# SAMA7D65D2GN8 register map
Vendor: Microchip Technology; Series: SAMA7D6; File version: 0
Registers are 32-bit, read-write, reset 0x0 unless marked. A register's access mark holds for its fields unless they carry their own. Offsets are from the block's base; [hi:lo] are bit positions; lines under a group give offsets from that group; <NAME> marks a mode.

## DDRUMCTL (part 4 of 4) — Enhanced Universal DDR-SDRAM Memory Controller
Base 0xE3800000; register names take the prefix UDDRC_
0xF04 SARBASE0 — SAR Base Address Register n
  [2:0] BASE_ADDR — Base address for address region n specified as awaddr[UMCTL2_A_ADDRW-1:x] and araddr[UMCTL2_A_ADDRW-1:x] where 'x' is determined by the minimum block size parameter UMCTL2_SARMINSIZE: (x=log2(block size)). Programming Mode: Static
0xF08 SARSIZE0 — SAR Size Register n
  [7:0] NBLOCKS — Number of blocks for address region n. This register determines the total size of the region in multiples of minimum block size as specified by the hardware parameter UMCTL2_SARMINSIZE. The register value is encoded as number of blocks = nblocks + 1. For example, if register is programmed to 0, region will have 1 block. Programming Mode: Static
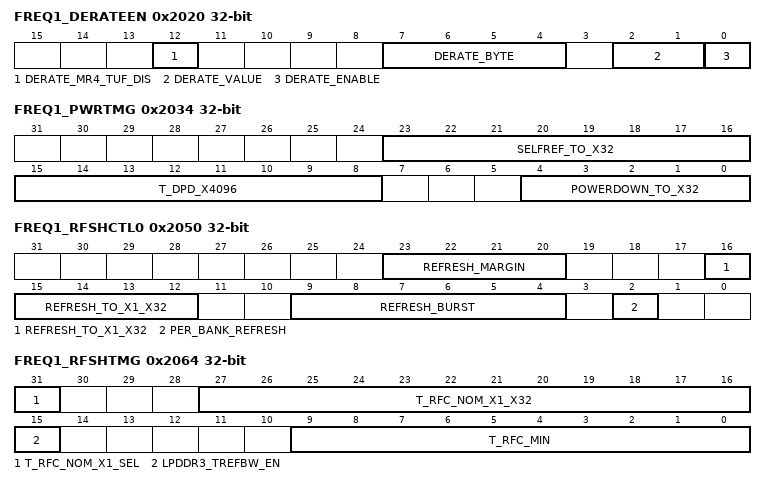
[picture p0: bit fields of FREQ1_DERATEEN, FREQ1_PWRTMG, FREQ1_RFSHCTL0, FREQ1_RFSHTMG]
0x2020 FREQ1_DERATEEN — [FREQ1] Temperature Derate Enable Register
  [12] DERATE_MR4_TUF_DIS — Disable use of MR4 TUF flag (MR4[7]) bit
  [7:4] DERATE_BYTE
  [2:1] DERATE_VALUE
  [0] DERATE_ENABLE — Enables derating
0x2024 FREQ1_DERATEINT reset 0x800000 — [FREQ1] Temperature Derate Interval Register
  [31:0] MR4_READ_INTERVAL — Interval between two MR4 reads
0x2034 FREQ1_PWRTMG — [FREQ1] Low Power Timing Register
  [23:16] SELFREF_TO_X32 — After this many clocks of the DDRC command channel being idle the UDDRC automatically puts the SDRAM into Self-refresh. The DDRC command channel is considered idle when there are no HIF commands outstanding. This must be enabled in the PWRCTL.selfref_en. For performance only. Unit: Multiples of 32 DFI clock cycles. Programming mode: Quasi-dynamic Group 4
  [15:8] T_DPD_X4096 — For LPDDR2/LPDDR3, value from the JEDEC specification is 500 s. Present only in designs configured to support LPDDR2 or LPDDR3. For performance only. Unit: Multiples of 4096 DFI clock cycles. Programming mode: Quasi-dynamic Group 4
  [4:0] POWERDOWN_TO_X32 — After this many clocks of the DDRC command channel being idle the UDDRC automatically puts the SDRAM into Power-down. The DDRC command channel is considered idle when there are no HIF commands outstanding. This must be enabled in the PWRCTL.powerdown_en. For performance only. Unit: Multiples of 32 DFI clock cycles. Programming mode: Quasi-dynamic Group 4
0x2050 FREQ1_RFSHCTL0 — [FREQ1] Refresh Control Register 0
  [23:20] REFRESH_MARGIN — Threshold value in number of DFI clock cycles before the critical refresh or page timer expires. A critical refresh is to be issued before this threshold is reached. It is recommended that this not be changed from the default value, currently shown as 0x2. It must always be less than internally used t_rfc_nom/32. Note that internally used t_rfc_nom is equal to RFSHTMG.t_rfc_nom_x1_x32 * 32 if RFSHTMG.t_rfc_nom_x1_sel=0. If RFSHTMG.t_rfc_nom_x1_sel=1 (for LPDDR2/LPDDR3/LPDDR4 per-bank refresh only), internally used t_rfc_nom is equal to RFSHTMG.t_rfc_nom_x1_x32. Note that, in LPDDR2/LPDDR3/LPDDR4, internally used t_rfc_nom may be divided by four if derating is enabled (DERATEEN.derate_enable=1). Unit: Multiples of 32 DFI clock cycles. Programming Mode: Dynamic - Refresh Related
  [16:12] REFRESH_TO_X1_X32 — If the refresh timer (tRFCnom, also known as tREFI) has expired at least once, then a speculative refresh may be performed. A speculative refresh is a refresh performed at a time when refresh would be useful. When the SDRAM bus is idle for a period of time determined by this RFSHCTL0.refresh_to_x1_x32 and the refresh timer has expired at least once since the last refresh, then a speculative refresh is performed. Speculative refreshes continues successively until there are no refreshes pending or until new reads or writes are issued to the uMCTL2. FOR PERFORMANCE ONLY. Unit: DFI clock cycles or multiples of 32 DFI clock cycles, depending on RFSHTMG.t_rfc_nom_x1_sel. Please refer to 'Note 1' from 'Notes on Timing Registers' at the start of 'Register Descriptions' chapter for details on how to program this register field. Programming Mode: Dynamic - Refresh Related
  [9:4] REFRESH_BURST — The programmed value + 1 is the number of refresh timeouts that is allowed to accumulate before traffic is blocked and the refreshes are forced to execute. Closing pages to perform a refresh is a one-time penalty that must be paid for each group of refreshes. Therefore, performing refreshes in a burst reduces the per-refresh penalty of these page closings. Higher numbers for RFSHCTL.refresh_burst slightly increases utilization; lower numbers decreases the worst-case latency associated with refreshes. - 0 - single refresh - 1 - burst-of-2 refresh - 7 - burst-of-8 refresh For information on burst refresh feature refer to section 3.9 of DDR2 JEDEC specification - JESD79-2F.pdf. For DDR2/3, the refresh is always per-rank and not per-bank. The rank refresh can be accumulated over 8*tREFI cycles using the burst refresh feature. In DDR4 mode, according to Fine Granularity feature, 8 refreshes can be postponed in 1X mode, 16 refreshes in 2X mode and 32 refreshes in 4X mode. If using PHY-initiated updates, care must be taken in the setting of RFSHCTL0.refresh_burst, to ensure that tRFCmax is not violated due to a PHY-initiated update occurring shortly before a refresh burst was due. In this situation, the refresh burst will be delayed until the PHY-initiated update is complete. In per-bank refresh mode of LPDDR2/LPDDR3/LPDDR4 (RFSHCTL0.per_bank_refresh = 1), 64 refreshes can be postponed. Programming Mode: Dynamic - Refresh Related
  [2] PER_BANK_REFRESH — - 1 - Per bank refresh - 0 - All bank refresh Per bank refresh allows traffic to flow to other banks. Per bank refresh is not supported by all LPDDR2 devices but should be supported by all LPDDR3/LPDDR4 devices. Present only in designs configured to support LPDDR2/LPDDR3/LPDDR4 Programming Mode: Static
0x2064 FREQ1_RFSHTMG — [FREQ1] Refresh Timing Register
  [31] T_RFC_NOM_X1_SEL — Specifies whether the RFSHTMG.t_rfc_nom_x1_x32 and RFSHCTL0.refresh_to_x1_x32 register values are x1 or x32. - 0 - x32 register values are used - 1 - x1 register values are used. This applies only when per-bank refresh is enabled (RFSHCTL0.per_bank_refresh=1); if per-bank refresh is not enabled, the x32 register values are used and this register field is ignored Programming Mode: Dynamic - Refresh Related
  [27:16] T_RFC_NOM_X1_X32 — Average time interval between refreshes per rank (Specification: 7.8us for DDR2, DDR3 and DDR4. See JEDEC specification for mDDR, LPDDR2, LPDDR3 and LPDDR4). When the controller is operating in 1:1 mode, set this register to RoundDown(tREFI/tCK) When the controller is operating in 1:2 mode, set this register to RoundDown(RoundDown(tREFI/tCK)/2) In both the above cases, if RFSHTMG.t_rfc_nom_x1_sel = 0, divide the above result by 32 and round down. For LPDDR2/LPDDR3/LPDDR4: - if using all-bank refreshes (RFSHCTL0.per_bank_refresh = 0), use tREFIab in the above calculations - if using per-bank refreshes (RFSHCTL0.per_bank_refresh = 1), use tREFIpb in the above calculations For DDR4 mode, tREFI value is different depending on the refresh mode. The user should program the appropriate value from the spec based on the value programmed in the refresh mode register. Note that: - RFSHTMG.t_rfc_nom_x1_x32 must be greater than 0x1. - if RFSHTMG.t_rfc_nom_x1_sel == 1, RFSHTMG.t_rfc_nom_x1_x32 must be greater than RFSHTMG.t_rfc_min - if RFSHTMG.t_rfc_nom_x1_sel == 0, RFSHTMG.t_rfc_nom_x1_x32 * 32 must be greater than RFSHTMG.t_rfc_min - In non-DDR4 or DDR4 Fixed 1x mode: RFSHTMG.t_rfc_nom_x1_x32 must be less than or equal to 0xFFE. - In DDR4 Fixed 2x mode: RFSHTMG.t_rfc_nom_x1_x32 must be less than or equal to 0x7FF. - In DDR4 Fixed 4x mode: RFSHTMG.t_rfc_nom_x1_x32 must be less than or equal to 0x3FF. Unit: DFI clock cycles or multiples of 32 DFI clock cycles, depending on RFSHTMG.t_rfc_nom_x1_sel. Please refer to 'Note 1' from 'Notes on Timing Registers' at the start of 'Register Descriptions' chapter for details on how to program this register field. Programming Mode: Dynamic - Refresh Related
  [15] LPDDR3_TREFBW_EN — Used only when LPDDR3 memory type is connected. Should only be changed when uMCTL2 is in reset. Specifies whether to use the tREFBW parameter (required by some LPDDR3 devices which comply with earlier versions of the LPDDR3 JEDEC specification) or not: - 0 - tREFBW parameter not used - 1 - tREFBW parameter used Programming Mode: Static
  [9:0] T_RFC_MIN — tRFC (min): Minimum time from refresh to refresh or activate. When the controller is operating in 1:1 mode, t_rfc_min should be set to RoundUp(tRFCmin/tCK). When the controller is operating in 1:2 mode, t_rfc_min should be set to RoundUp(RoundUp(tRFCmin/tCK)/2). In LPDDR2/LPDDR3/LPDDR4 mode: - if using all-bank refreshes, the tRFCmin value in the above equations is equal to tRFCab - if using per-bank refreshes, the tRFCmin value in the above equations is equal to tRFCpb In DDR4 mode, the tRFCmin value in the above equations is different depending on the refresh mode (fixed 1X,2X,4X) and the device density. The user should program the appropriate value from the spec based on the 'refresh_mode' and the device density that is used. Unit: DFI clock cycles. Programming Mode: Dynamic - Refresh Related
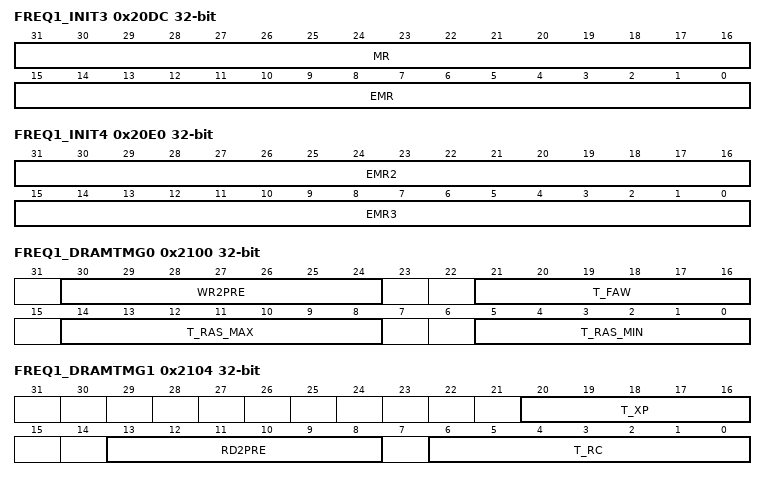
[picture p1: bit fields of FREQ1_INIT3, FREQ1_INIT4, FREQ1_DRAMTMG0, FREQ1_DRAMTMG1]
0x20DC FREQ1_INIT3 — [FREQ1] SDRAM Initialization Register 3
  [31:16] MR — DDR2: Value to write to MR register. Bit 8 is for DLL and the setting here is ignored. The uMCTL2 sets this bit appropriately. DDR3/DDR4: Value loaded into MR0 register. mDDR: Value to write to MR register. LPDDR2/LPDDR3/LPDDR4 - Value to write to MR1 register Programming Mode: Quasi-dynamic Group 1, Group 4
  [15:0] EMR — DDR2: Value to write to EMR register. Bits 9:7 are for OCD and the setting in this register is ignored. The uMCTL2 sets those bits appropriately. DDR3/DDR4: Value to write to MR1 register Set bit 7 to 0. mDDR: Value to write to EMR register. LPDDR2/LPDDR3/LPDDR4 - Value to write to MR2 register Programming Mode: Quasi-dynamic Group 4
0x20E0 FREQ1_INIT4 — [FREQ1] SDRAM Initialization Register 4
  [31:16] EMR2 — DDR2: Value to write to EMR2 register. DDR3/DDR4: Value to write to MR2 register LPDDR2/LPDDR3/LPDDR4: Value to write to MR3 register mDDR: Unused Programming Mode: Quasi-dynamic Group 4
  [15:0] EMR3 — DDR2: Value to write to EMR3 register. DDR3/DDR4: Value to write to MR3 register mDDR/LPDDR2/LPDDR3: Unused LPDDR4: Value to write to MR13 register Programming Mode: Quasi-dynamic Group 2, Group 4
0x2100 FREQ1_DRAMTMG0 — [FREQ1] SDRAM Timing Register 0
  [30:24] WR2PRE — Minimum time between write and precharge to same bank. Specifications: WL + BL/2 + tWR = approximately 8 cycles + 15 ns = 14 clocks @400MHz and less for lower frequencies where: - WL = write latency - BL = burst length. This must match the value programmed in the BL bit of the mode register to the SDRAM. BST (burst terminate) is not supported at present. - tWR = Write recovery time. This comes directly from the SDRAM specification. Add one extra cycle for LPDDR2/LPDDR3/LPDDR4 for this parameter. When the controller is operating in 1:2 frequency ratio mode, 1T mode, divide the above value by 2. No rounding up. When the controller is operating in 1:2 frequency ratio mode, 2T mode or LPDDR4 mode, divide the above value by 2 and round it up to the next integer value. Note that, depending on the PHY, if using LRDIMM, it may be necessary to adjust the value of this parameter to compensate for the extra cycle of latency through the LRDIMM. Unit: DFI clock cycles. Programming Mode: Quasi-dynamic Group 1, Group 2, Group 4
  [21:16] T_FAW — tFAW Valid only when 8 or more banks(or banks 'x' bank groups) are present. In 8-bank design, at most 4 banks must be activated in a rolling window of tFAW cycles. When the controller is operating in 1:2 frequency ratio mode, program this to (tFAW/2) and round up to next integer value. In a 4-bank design, set this register to 0x1 independent of the 1:1/1:2 frequency mode. Unit: DFI clock cycles. Programming Mode: Quasi-dynamic Group 2, Group 4
  [14:8] T_RAS_MAX — tRAS(max): Maximum time between activate and precharge to same bank. This is the maximum time that a page can be kept open Minimum value of this register is 1. Zero is invalid. When the controller is operating in 1:1 frequency ratio mode, t_ras_max should be set to RoundDown(tRAS(max)/tCK/1024). When the controller is operating in 1:2 frequency ratio mode, t_ras_max should be set to RoundDown((RoundDown(tRAS(max)/tCK/1024)-1)/2). Unit: Multiples of 1024 DFI clock cycles. Programming Mode: Quasi-dynamic Group 2, Group 4
  [5:0] T_RAS_MIN — tRAS(min): Minimum time between activate and precharge to the same bank. When the controller is operating in 1:2 frequency mode, 1T mode, program this to tRAS(min)/2. No rounding up. When the controller is operating in 1:2 frequency ratio mode, 2T mode or LPDDR4 mode, program this to (tRAS(min)/2) and round it up to the next integer value. Unit: DFI clock cycles. Programming Mode: Quasi-dynamic Group 2, Group 4
0x2104 FREQ1_DRAMTMG1 — [FREQ1] SDRAM Timing Register 1
  [20:16] T_XP — tXP: Minimum time after power-down exit to any operation. For DDR3, this should be programmed to tXPDLL if slow powerdown exit is selected in MR0[12]. If C/A parity for DDR4 is used, set to (tXP+PL) instead. If LPDDR4 is selected and its spec has tCKELPD parameter, set to the larger of tXP and tCKELPD instead. When the controller is operating in 1:2 frequency ratio mode, program this to (tXP/2) and round it up to the next integer value. Units: DFI clock cycles. Programming Mode: Quasi-dynamic Group 2, Group 4
  [13:8] RD2PRE — tRTP: Minimum time from read to precharge of same bank. - DDR2: tAL + BL/2 + max(tRTP, 2) - 2 - DDR3: tAL + max (tRTP, 4) - DDR4: Max of following two equations: tAL + max (tRTP, 4) or, RL + BL/2 - tRP (*). - mDDR: BL/2 - LPDDR2: Depends on if it's LPDDR2-S2 or LPDDR2-S4: LPDDR2-S2: BL/2 + tRTP - 1. LPDDR2-S4: BL/2 + max(tRTP,2) - 2. - LPDDR3: BL/2 + max(tRTP,4) - 4 - LPDDR4: BL/2 + max(tRTP,8) - 8 (*) When both DDR4 SDRAM and ST-MRAM are used simultaneously, use SDRAM's tRP value for calculation. When the controller is operating in 1:2 mode, 1T mode, divide the above value by 2. No rounding up. When the controller is operating in 1:2 mode, 2T mode or LPDDR4 mode, divide the above value by 2 and round it up to the next integer value. Unit: DFI clock cycles. Programming Mode: Quasi-dynamic Group 1, Group 2, Group 4
  [6:0] T_RC — tRC: Minimum time between activates to same bank. When the controller is operating in 1:2 frequency ratio mode, program this to (tRC/2) and round up to next integer value. Unit: DFI clock cycles. Programming Mode: Quasi-dynamic Group 2, Group 4
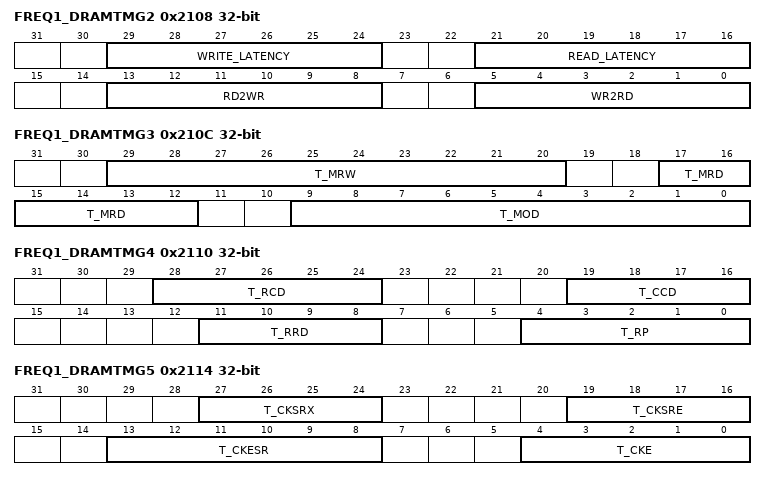
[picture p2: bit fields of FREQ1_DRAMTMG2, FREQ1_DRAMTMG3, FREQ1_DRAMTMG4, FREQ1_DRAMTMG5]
0x2108 FREQ1_DRAMTMG2 — [FREQ1] SDRAM Timing Register 2
  [29:24] WRITE_LATENCY — Set to WL Time from write command to write data on SDRAM interface. This must be set to WL. For mDDR, it should normally be set to 1. Note that, depending on the PHY, if using RDIMM/LRDIMM, it may be necessary to adjust the value of WL to compensate for the extra cycle of latency through the RDIMM/LRDIMM. When the controller is operating in 1:2 frequency ratio mode, divide the value calculated using the above equation by 2, and round it up to next integer. This register field is not required for DDR2 and DDR3, as the DFI read and write latencies defined in DFITMG0 and DFITMG1 are sufficient for those protocols For all protocols, in addition to programming this register field, it is necessary to program DFITMG0 and DFITMG1 to control the read and write latencies Unit: DFI clock cycles. Programming Mode: Quasi-dynamic Group 1, Group 2, Group 4
  [21:16] READ_LATENCY — Set to RL Time from read command to read data on SDRAM interface. This must be set to RL. Note that, depending on the PHY, if using RDIMM/LRDIMM, it may be necessary to adjust the value of RL to compensate for the extra cycle of latency through the RDIMM/LRDIMM. When the controller is operating in 1:2 frequency ratio mode, divide the value calculated using the above equation by 2, and round it up to next integer. This register field is not required for DDR2 and DDR3, as the DFI read and write latencies defined in DFITMG0 and DFITMG1 are sufficient for those protocols For all protocols, in addition to programming this register field, it is necessary to program DFITMG0 and DFITMG1 to control the read and write latencies Unit: DFI clock cycles. Programming Mode: Quasi-dynamic Group 1, Group 2, Group 4
  [13:8] RD2WR — DDR2/3/mDDR: RL + BL/2 + 2 - WL DDR4: RL + BL/2 + 1 + WR_PREAMBLE - WL LPDDR2/LPDDR3: RL + BL/2 + RU(tDQSCKmax/tCK) + 1 - WL LPDDR4(DQ ODT is Disabled): RL + BL/2 + RU(tDQSCKmax/tCK) + WR_PREAMBLE + RD_POSTAMBLE - WL LPDDR4(DQ ODT is Enabled) : RL + BL/2 + RU(tDQSCKmax/tCK) + RD_POSTAMBLE - ODTLon - RU(tODTon(min)/tCK) + 1 Minimum time from read command to write command. Include time for bus turnaround and all per-bank, per-rank, and global constraints. Please see the relevant PHY databook for details of what should be included here. Where: - WL = write latency - BL = burst length. This must match the value programmed in the BL bit of the mode register to the SDRAM - RL = read latency = CAS latency - WR_PREAMBLE = 1 (1tCK write preamble), 2 (2tCK write preamble). This is unique to DDR4 and LPDDR4. - RD_POSTAMBLE = 0.5 (0.5tCK read postamble), 1.5 (1.5tCK read postamble). This is unique to LPDDR4. After PHY has completed training the value programmed may need to be increased. Refer to relevant PHY documentation. For LPDDR2/LPDDR3/LPDDR4, if derating is enabled (DERATEEN.derate_enable=1), derated tDQSCKmax should be used. When the controller is operating in 1:2 frequency ratio mode, divide the value calculated using the above equation by 2, and round it up to next integer. Note that, depending on the PHY, if using LRDIMM, it may be necessary to adjust the value of this parameter to compensate for the extra cycle of latency through the LRDIMM. Unit: DFI clock cycles. Programming Mode: Quasi-dynamic Group 1, Group 2, Group 4
  [5:0] WR2RD — DDR4: CWL + PL + BL/2 + tWTR_L LPDDR2/3/4: WL + BL/2 + tWTR + 1 Others: CWL + BL/2 + tWTR In DDR4, minimum time from write command to read command for same bank group. In others, minimum time from write command to read command. Includes time for bus turnaround, recovery times, and all per-bank, per-rank, and global constraints. Please see the relevant PHY databook for details of what should be included here. Where: - CWL = CAS write latency - WL = Write latency - PL = Parity latency - BL = burst length. This must match the value programmed in the BL bit of the mode register to the SDRAM - tWTR_L = internal write to read command delay for same bank group. This comes directly from the SDRAM specification. - tWTR = internal write to read command delay. This comes directly from the SDRAM specification. After PHY has completed training the value programmed may need to be increased. Refer to relevant PHY documentation. Add one extra cycle for LPDDR2/LPDDR3/LPDDR4 operation. WTR_L should be increased by one if DDR4 2tCK write preamble is used. When the controller is operating in 1:2 mode, divide the value calculated using the above equation by 2, and round it up to next integer. Unit: DFI clock cycles. Programming Mode: Quasi-dynamic Group 1, Group 2, Group 4
0x210C FREQ1_DRAMTMG3 — [FREQ1] SDRAM Timing Register 3
  [29:20] T_MRW — Time to wait after a mode register write or read (MRW or MRR). Present only in designs configured to support LPDDR2, LPDDR3 or LPDDR4. LPDDR2 typically requires value of 5. LPDDR3 typically requires value of 10. LPDDR4: Set this to the larger of tMRW and tMRWCKEL. For LPDDR2, this register is used for the time from a MRW/MRR to all other commands. When the controller is operating in 1:2 frequency ratio mode, program this to the above values divided by 2 and round it up to the next integer value. For LDPDR3, this register is used for the time from a MRW/MRR to a MRW/MRR. Unit: DFI clock cycles. Programming Mode: Quasi-dynamic Group 2, Group 4
  [17:12] T_MRD — tMRD: Cycles to wait after a mode register write or read. Depending on the connected SDRAM, tMRD represents: DDR2/mDDR: Time from MRS to any command DDR3/4: Time from MRS to MRS command LPDDR2: not used LPDDR3/4: Time from MRS to non-MRS command. When the controller is operating in 1:2 frequency ratio mode, program this to (tMRD/2) and round it up to the next integer value. If C/A parity for DDR4 is used, set to tMRD_PAR(tMOD+PL) instead. If CAL mode is enabled (DFITMG1.dfi_t_cmd_lat > 0), tCAL (=DFITMG1.dfi_cmd_lat) should be added to the above calculations. Unit: DFI clock cycles. Programming Mode: Quasi-dynamic Group 2, Group 4
  [9:0] T_MOD — tMOD: Parameter used only in DDR3 and DDR4. Cycles between load mode command and following non-load mode command. If C/A parity for DDR4 is used, set to tMOD_PAR(tMOD+PL) instead. If CAL mode is enabled (DFITMG1.dfi_t_cmd_lat > 0), tCAL (=DFITMG1.dfi_cmd_lat) should be added to the above calculations. If MPR writes for DDR4 are used, set to tMOD + AL (or tMPD_PAR + AL if C/A parity is also used). Set to tMOD if controller is operating in 1:1 frequency ratio mode, or tMOD/2 (rounded up to next integer) if controller is operating in 1:2 frequency ratio mode. Note that if using RDIMM/LRDIMM, depending on the PHY, it may be necessary to adjust the value of this parameter to compensate for the extra cycle of latency applied to mode register writes by the RDIMM/LRDIMM chip. Also note that if using LRDIMM, the minimum value of this register is tMRD_L2 if controller is operating in 1:1 frequency ratio mode, or tMRD_L2/2 (rounded up to next integer) if controller is operating in 1:2 frequency ratio mode. Unit: DFI clock cycles. Programming Mode: Quasi-dynamic Group 2, Group 4
0x2110 FREQ1_DRAMTMG4 — [FREQ1] SDRAM Timing Register 4
  [28:24] T_RCD — tRCD - tAL: Minimum time from activate to read or write command to same bank. When the controller is operating in 1:2 frequency ratio mode, program this to ((tRCD - tAL)/2) and round it up to the next integer value. Minimum value allowed for this register is 1, which implies minimum (tRCD - tAL) value to be 2 when the controller is operating in 1:2 frequency ratio mode. Unit: DFI clock cycles. Programming Mode: Quasi-dynamic Group 1, Group 2, Group 4
  [19:16] T_CCD — DDR4: tCCD_L: This is the minimum time between two reads or two writes for same bank group. Others: tCCD: This is the minimum time between two reads or two writes. When the controller is operating in 1:2 frequency ratio mode, program this to (tCCD_L/2 or tCCD/2) and round it up to the next integer value. Unit: DFI clock cycles. Programming Mode: Quasi-dynamic Group 2, Group 4
  [11:8] T_RRD — DDR4: tRRD_L: Minimum time between activates from bank 'a' to bank 'b' for same bank group. Others: tRRD: Minimum time between activates from bank 'a' to bank 'b' When the controller is operating in 1:2 frequency ratio mode, program this to (tRRD_L/2 or tRRD/2) and round it up to the next integer value. Unit: DFI clock cycles. Programming Mode: Quasi-dynamic Group 2, Group 4
  [4:0] T_RP — tRP: Minimum time from single-bank precharge to activate of same bank. When the controller is operating in 1:1 frequency ratio mode, t_rp should be set to RoundUp(tRP/tCK). When the controller is operating in 1:2 frequency ratio mode, t_rp should be set to RoundDown(RoundUp(tRP/tCK)/2) + 1. When the controller is operating in 1:2 frequency ratio mode in LPDDR4, t_rp should be set to RoundUp(RoundUp(tRP/tCK)/2). Unit: DFI clock cycles. Programming Mode: Quasi-dynamic Group 2, Group 4
0x2114 FREQ1_DRAMTMG5 — [FREQ1] SDRAM Timing Register 5
  [27:24] T_CKSRX — This is the time before Self Refresh Exit that CK is maintained as a valid clock before issuing SRX. Specifies the clock stable time before SRX. Recommended settings: - mDDR: 1 - LPDDR2: 2 - LPDDR3: 2 - LPDDR4: tCKCKEH - DDR2: 1 - DDR3: tCKSRX - DDR4: tCKSRX When the controller is operating in 1:2 frequency ratio mode, program this to recommended value divided by two and round it up to next integer. Unit: DFI clock cycles. Programming Mode: Quasi-dynamic Group 2, Group 4
  [19:16] T_CKSRE — This is the time after Self Refresh Down Entry that CK is maintained as a valid clock. Specifies the clock disable delay after SRE. Recommended settings: - mDDR: 0 - LPDDR2: 2 - LPDDR3: 2 - LPDDR4: tCKELCK - DDR2: 1 - DDR3: max (10 ns, 5 tCK) - DDR4: max (10 ns, 5 tCK) (+ PL(parity latency)(*)) (*)Only if CRCPARCTL1.caparity_disable_before_sr=0, this register should be increased by PL. When the controller is operating in 1:2 frequency ratio mode, program this to recommended value divided by two and round it up to next integer. Unit: DFI clock cycles. Programming Mode: Quasi-dynamic Group 2, Group 4
  [13:8] T_CKESR — Minimum CKE low width for Self refresh or Self refresh power down entry to exit timing in memory clock cycles. Recommended settings: - mDDR: tRFC - LPDDR2: tCKESR - LPDDR3: tCKESR - LPDDR4: max(tCKE, tSR) - DDR2: tCKE - DDR3: tCKE + 1 - DDR4: tCKE + 1 (+ PL(parity latency)(*)) (*)Only if CRCPARCTL1.caparity_disable_before_sr=0, this register should be increased by PL. When the controller is operating in 1:2 frequency ratio mode, program this to recommended value divided by two and round it up to next integer. Unit: DFI clock cycles. Programming Mode: Quasi-dynamic Group 2, Group 4
  [4:0] T_CKE — Minimum number of cycles of CKE HIGH/LOW during power-down and self refresh. - LPDDR2/LPDDR3 mode: Set this to the larger of tCKE or tCKESR - LPDDR4 mode: Set this to the larger of tCKE or tSR. - Non-LPDDR2/non-LPDDR3/non-LPDDR4 designs: Set this to tCKE value. When the controller is operating in 1:2 frequency ratio mode, program this to (value described above)/2 and round it up to the next integer value. Unit: DFI clock cycles. Programming Mode: Quasi-dynamic Group 2, Group 4
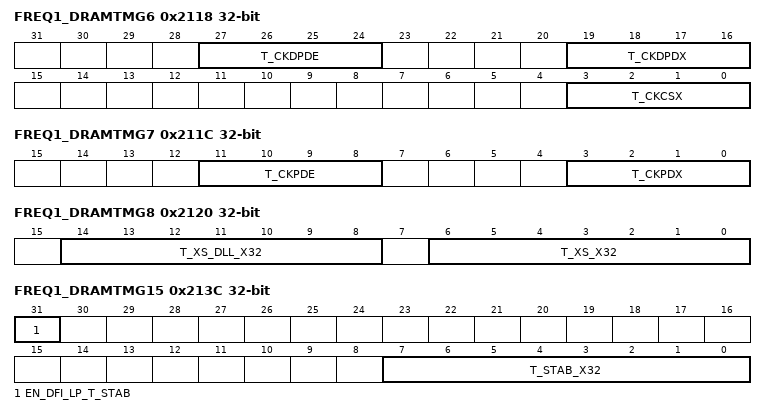
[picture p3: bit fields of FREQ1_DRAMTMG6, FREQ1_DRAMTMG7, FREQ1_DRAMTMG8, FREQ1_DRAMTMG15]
0x2118 FREQ1_DRAMTMG6 — [FREQ1] SDRAM Timing Register 6
  [27:24] T_CKDPDE — This is the time after Deep Power Down Entry that CK is maintained as a valid clock. Specifies the clock disable delay after DPDE. Recommended settings: - mDDR: 0 - LPDDR2: 2 - LPDDR3: 2 When the controller is operating in 1:2 frequency ratio mode, program this to recommended value divided by two and round it up to next integer. This is only present for designs supporting mDDR or LPDDR2/LPDDR3 devices. Unit: DFI clock cycles. Programming Mode: Quasi-dynamic Group 2, Group 4
  [19:16] T_CKDPDX — This is the time before Deep Power Down Exit that CK is maintained as a valid clock before issuing DPDX. Specifies the clock stable time before DPDX. Recommended settings: - mDDR: 1 - LPDDR2: 2 - LPDDR3: 2 When the controller is operating in 1:2 frequency ratio mode, program this to recommended value divided by two and round it up to next integer. This is only present for designs supporting mDDR or LPDDR2 devices. Unit: DFI clock cycles. Programming Mode: Quasi-dynamic Group 2, Group 4
  [3:0] T_CKCSX — This is the time before Clock Stop Exit that CK is maintained as a valid clock before issuing Clock Stop Exit. Specifies the clock stable time before next command after Clock Stop Exit. Recommended settings: - mDDR: 1 - LPDDR2: tXP + 2 - LPDDR3: tXP + 2 - LPDDR4: tXP + 2 When the controller is operating in 1:2 frequency ratio mode, program this to recommended value divided by two and round it up to next integer. This is only present for designs supporting mDDR or LPDDR2/LPDDR3/LPDDR4 devices. Unit: DFI clock cycles. Programming Mode: Quasi-dynamic Group 2, Group 4
0x211C FREQ1_DRAMTMG7 — [FREQ1] SDRAM Timing Register 7
  [11:8] T_CKPDE — This is the time after Power Down Entry that CK is maintained as a valid clock. Specifies the clock disable delay after PDE. Recommended settings: - mDDR: 0 - LPDDR2: 2 - LPDDR3: 2 - LPDDR4: tCKELCK When using DDR2/3/4 SDRAM, this register should be set to the same value as DRAMTMG5.t_cksre. When the controller is operating in 1:2 frequency ratio mode, program this to recommended value divided by two and round it up to next integer. This is only present for designs supporting mDDR or LPDDR2/LPDDR3/LPDDR4 devices. Unit: DFI clock cycles. Programming Mode: Quasi-dynamic Group 2, Group 4
  [3:0] T_CKPDX — This is the time before Power Down Exit that CK is maintained as a valid clock before issuing PDX. Specifies the clock stable time before PDX. Recommended settings: - mDDR: 0 - LPDDR2: 2 - LPDDR3: 2 - LPDDR4: tCKCKEH When using DDR2/3/4 SDRAM, this register should be set to the same value as DRAMTMG5.t_cksrx. When the controller is operating in 1:2 frequency ratio mode, program this to recommended value divided by two and round it up to next integer. This is only present for designs supporting mDDR or LPDDR2/LPDDR3/LPDDR4 devices. Unit: DFI clock cycles. Programming Mode: Quasi-dynamic Group 2, Group 4
0x2120 FREQ1_DRAMTMG8 — [FREQ1] SDRAM Timing Register 8
  [14:8] T_XS_DLL_X32 — tXSDLL: Exit Self Refresh to commands requiring a locked DLL. When the controller is operating in 1:2 frequency ratio mode, program this to the above value divided by 2 and round up to next integer value. Note: Used only for DDR2, DDR3 and DDR4 SDRAMs. Unit: Multiples of 32 DFI clock cycles. Please refer to 'Note 1' from 'Notes on Timing Registers' at the start of 'Register Descriptions' chapter for details on how to program this register field. Programming Mode: Quasi-dynamic Group 2, Group 4
  [6:0] T_XS_X32 — tXS: Exit Self Refresh to commands not requiring a locked DLL. When the controller is operating in 1:2 frequency ratio mode, program this to the above value divided by 2 and round up to next integer value. Note: Used only for DDR2, DDR3 and DDR4 SDRAMs. Unit: Multiples of 32 DFI clock cycles. Please refer to 'Note 1' from 'Notes on Timing Registers' at the start of 'Register Descriptions' chapter for details on how to program this register field. Programming Mode: Quasi-dynamic Group 2, Group 4
0x2138 FREQ1_DRAMTMG14 — [FREQ1] SDRAM Timing Register 14
  [11:0] T_XSR — tXSR: Exit Self Refresh to any command. When the controller is operating in 1:2 frequency ratio mode, program this to the above value divided by 2 and round up to next integer value. The value 0xfff is illegal for this register field. Note: Used only for mDDR/LPDDR2/LPDDR3/LPDDR4 mode. Unit: DFI clock cycles. Programming Mode: Quasi-dynamic Group 2, Group 4
0x213C FREQ1_DRAMTMG15 — [FREQ1] SDRAM Timing Register 15
  [31] EN_DFI_LP_T_STAB — - 1 - Enable using tSTAB when exiting DFI LP. Needs to be set when the PHY is stopping the clock during DFI LP to save maximum power. - 0 - Disable using tSTAB when exiting DFI LP Programming Mode: Quasi-dynamic Group 2, Group 4
  [7:0] T_STAB_X32 — tSTAB: Stabilization time. It is required in the following two cases for DDR3/DDR4 RDIMM : - when exiting power saving mode, if the clock was stopped, after re-enabling it the clock must be stable for a time specified by tSTAB - in the case of input clock frequency change (DDR4) - after issuing control words that refers to clock timing (Specification: 6us for DDR3, 5us for DDR4) When the controller is operating in 1:2 frequency ratio mode, program this to recommended value divided by two and round it up to next integer. Unit: Multiples of 32 DFI clock cycles. Please refer to 'Note 1' from 'Notes on Timing Registers' at the start of 'Register Descriptions' chapter for details on how to program this register field. Programming Mode: Quasi-dynamic Group 2, Group 4
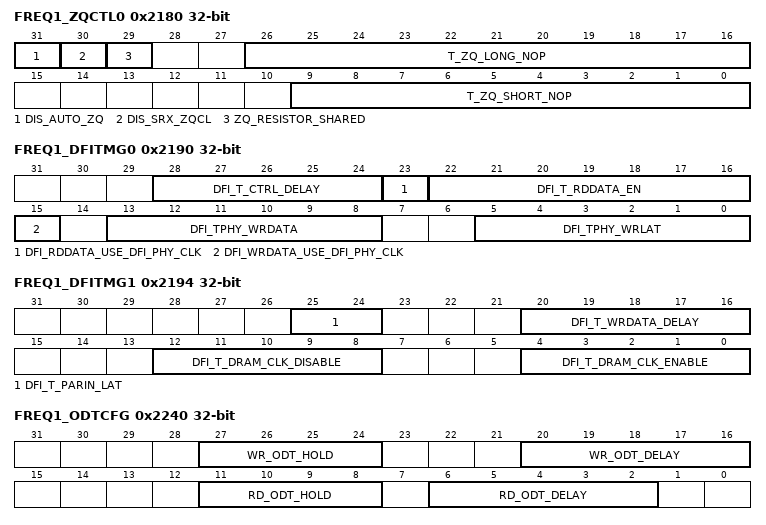
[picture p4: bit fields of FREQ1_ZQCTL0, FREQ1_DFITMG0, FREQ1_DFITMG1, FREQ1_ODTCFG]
0x2180 FREQ1_ZQCTL0 — [FREQ1] ZQ Control Register 0
  [31] DIS_AUTO_ZQ — - 1 - Disable uMCTL2 generation of ZQCS/MPC(ZQ calibration) command. Register DBGCMD.zq_calib_short can be used instead to issue ZQ calibration request from APB module. - 0 - Internally generate ZQCS/MPC(ZQ calibration) commands based on ZQCTL1.t_zq_short_interval_x1024. This is only present for designs supporting DDR3/DDR4 or LPDDR2/LPDDR3/LPDDR4 devices. Programming Mode: Dynamic
  [30] DIS_SRX_ZQCL — - 1 - Disable issuing of ZQCL/MPC(ZQ calibration) command at Self-Refresh/SR-Powerdown exit. Only applicable when run in DDR3 or DDR4 or LPDDR2 or LPDDR3 or LPDDR4 mode. - 0 - Enable issuing of ZQCL/MPC(ZQ calibration) command at Self-Refresh/SR-Powerdown exit. Only applicable when run in DDR3 or DDR4 or LPDDR2 or LPDDR3 or LPDDR4 mode. This is only present for designs supporting DDR3/DDR4 or LPDDR2/LPDDR3/LPDDR4 devices. Programming Mode: Quasi-dynamic Group 2, Group 4
  [29] ZQ_RESISTOR_SHARED — - 1 - Denotes that ZQ resistor is shared between ranks. Means ZQinit/ZQCL/ZQCS/MPC(ZQ calibration) commands are sent to one rank at a time with tZQinit/tZQCL/tZQCS/tZQCAL/tZQLAT timing met between commands so that commands to different ranks do not overlap. - 0 - ZQ resistor is not shared. This is only present for designs supporting DDR3/DDR4 or LPDDR2/LPDDR3/LPDDR4 devices. Programming Mode: Static
  [26:16] T_ZQ_LONG_NOP — tZQoper for DDR3/DDR4, tZQCL for LPDDR2/LPDDR3, tZQCAL for LPDDR4: Number of DFI clock cycles of NOP required after a ZQCL (ZQ calibration long)/MPC(ZQ Start) command is issued to SDRAM. When the controller is operating in 1:2 frequency ratio mode: DDR3/DDR4: program this to tZQoper/2 and round it up to the next integer value. LPDDR2/LPDDR3: program this to tZQCL/2 and round it up to the next integer value. LPDDR4: program this to tZQCAL/2 and round it up to the next integer value. This is only present for designs supporting DDR3/DDR4 or LPDDR2/LPDDR3/LPDDR4 devices. Unit: DFI clock cycles. Programming Mode: Static
  [9:0] T_ZQ_SHORT_NOP — tZQCS for DDR3/DD4/LPDDR2/LPDDR3, tZQLAT for LPDDR4: Number of DFI clock cycles of NOP required after a ZQCS (ZQ calibration short)/MPC(ZQ Latch) command is issued to SDRAM. When the controller is operating in 1:2 frequency ratio mode, program this to tZQCS/2 and round it up to the next integer value. This is only present for designs supporting DDR3/DDR4 or LPDDR2/LPDDR3/LPDDR4 devices. Unit: DFI clock cycles. Programming Mode: Static
0x2190 FREQ1_DFITMG0 — [FREQ1] DFI Timing Register 0
  [28:24] DFI_T_CTRL_DELAY — Specifies the number of DFI clock cycles after an assertion or de-assertion of the DFI control signals that the control signals at the PHY-DRAM interface reflect the assertion or de-assertion. If the DFI clock and the memory clock are not phase-aligned, this timing parameter should be rounded up to the next integer value. Note that if using RDIMM/LRDIMM, it is necessary to increment this parameter by RDIMM's/LRDIMM's extra cycle of latency in terms of DFI clock. Unit: DFI clock cycles. Programming Mode: Quasi-dynamic Group 4
  [23] DFI_RDDATA_USE_DFI_PHY_CLK — Defines whether dfi_rddata_en/dfi_rddata/dfi_rddata_valid is generated using HDR (DFI clock) or SDR (DFI PHY clock) values. Selects whether value in DFITMG0.dfi_t_rddata_en is in terms of HDR (DFI clock) or SDR (DFI PHY clock) cycles: - 0 in terms of HDR (DFI clock) cycles - 1 in terms of SDR (DFI PHY clock) cycles Refer to PHY specification for correct value. If using a Synopsys DWC DDR3/2 PHY, DWC DDR2/3-Lite/mDDR PHY, DWC DDR multiPHY or DWC Gen2 DDR multiPHY, this field must be set to 0; otherwise: - If MEMC_PROG_FREQ_RATIO=1 and MSTR.frequency_ratio=1, this field should be set to 0 - Else, it must be set to 1 Programming Mode: Static
  [22:16] DFI_T_RDDATA_EN — Time from the assertion of a read command on the DFI interface to the assertion of the dfi_rddata_en signal. Refer to PHY specification for correct value. This corresponds to the DFI parameter trddata_en. Note that, depending on the PHY, if using RDIMM/LRDIMM, it may be necessary to use the adjusted value of CL in the calculation of trddata_en. This is to compensate for the extra cycle(s) of latency through the RDIMM/LRDIMM. Unit: DFI clock cycles or DFI PHY clock cycles, depending on DFITMG0.dfi_rddata_use_dfi_phy_clk. Programming Mode: Quasi-dynamic Group 1, Group 4
  [15] DFI_WRDATA_USE_DFI_PHY_CLK — Defines whether dfi_wrdata_en/dfi_wrdata/dfi_wrdata_mask is generated using HDR (DFI clock) or SDR (DFI PHY clock) values Selects whether value in DFITMG0.dfi_tphy_wrlat is in terms of HDR (DFI clock) or SDR (DFI PHY clock) cycles Selects whether value in DFITMG0.dfi_tphy_wrdata is in terms of HDR (DFI clock) or SDR (DFI PHY clock) cycles - 0 in terms of HDR (DFI clock) cycles - 1 in terms of SDR (DFI PHY clock) cycles Refer to PHY specification for correct value. If using a Synopsys DWC DDR3/2 PHY, DWC DDR2/3-Lite/mDDR PHY, DWC DDR multiPHY or DWC Gen2 DDR multiPHY, this field must be set to 0; otherwise: - If MEMC_PROG_FREQ_RATIO=1 and MSTR.frequency_ratio=1, this field should be set to 0 - Else, it must be set to 1 Programming Mode: Static
  [13:8] DFI_TPHY_WRDATA — Specifies the number of clock cycles between when dfi_wrdata_en is asserted to when the associated write data is driven on the dfi_wrdata signal. This corresponds to the DFI timing parameter tphy_wrdata. Refer to PHY specification for correct value. Note, max supported value is 8. Unit: DFI clock cycles or DFI PHY clock cycles, depending on DFITMG0.dfi_wrdata_use_dfi_phy_clk. Programming Mode: Quasi-dynamic Group 4
  [5:0] DFI_TPHY_WRLAT — Write latency Number of clocks from the write command to write data enable (dfi_wrdata_en). This corresponds to the DFI timing parameter tphy_wrlat. Refer to PHY specification for correct value.Note that, depending on the PHY, if using RDIMM/LRDIMM, it may be necessary to use the adjusted value of CL in the calculation of tphy_wrlat. This is to compensate for the extra cycle(s) of latency through the RDIMM/LRDIMM. For LPDDR4, dfi_tphy_wrlat>60 is not supported. Unit: DFI clock cycles or DFI PHY clock cycles, depending on DFITMG0.dfi_wrdata_use_dfi_phy_clk. Programming Mode: Quasi-dynamic Group 1, Group 4
0x2194 FREQ1_DFITMG1 — [FREQ1] DFI Timing Register 1
  [25:24] DFI_T_PARIN_LAT — Specifies the number of DFI PHY clock cycles between when the dfi_cs signal is asserted and when the associated dfi_parity_in signal is driven. Unit: DFI PHY clock cycles. Programming Mode: Quasi-dynamic Group 4
  [20:16] DFI_T_WRDATA_DELAY — Specifies the number of DFI clock cycles between when the dfi_wrdata_en signal is asserted and when the corresponding write data transfer is completed on the DRAM bus. This corresponds to the DFI timing parameter twrdata_delay. Refer to PHY specification for correct value. For DFI 3.0 PHY, set to twrdata_delay, a new timing parameter introduced in DFI 3.0. For DFI 2.1 PHY, set to tphy_wrdata + (delay of DFI write data to the DRAM). Value to be programmed is in terms of DFI clocks, not PHY clocks. In FREQ_RATIO=2, divide PHY's value by 2 and round up to next integer. If using DFITMG0.dfi_wrdata_use_dfi_phy_clk=1, add 1 to the value. Unit: DFI clock cycles. Programming Mode: Quasi-dynamic Group 4
  [12:8] DFI_T_DRAM_CLK_DISABLE — Specifies the number of DFI clock cycles from the assertion of the dfi_dram_clk_disable signal on the DFI until the clock to the DRAM memory devices, at the PHY-DRAM boundary, maintains a low value. If the DFI clock and the memory clock are not phase aligned, this timing parameter should be rounded up to the next integer value. Unit: DFI clock cycles. Programming Mode: Quasi-dynamic Group 4
  [4:0] DFI_T_DRAM_CLK_ENABLE — Specifies the number of DFI clock cycles from the de-assertion of the dfi_dram_clk_disable signal on the DFI until the first valid rising edge of the clock to the DRAM memory devices, at the PHY-DRAM boundary. If the DFI clock and the memory clock are not phase aligned, this timing parameter should be rounded up to the next integer value. Unit: DFI clock cycles. Programming Mode: Quasi-dynamic Group 4
0x2240 FREQ1_ODTCFG — [FREQ1] ODT Configuration Register
  [27:24] WR_ODT_HOLD — DFI PHY clock cycles to hold ODT for a write command. The minimum supported value is 2. Recommended values: DDR2: - BL8: 0x5 (DDR2-400/533/667), 0x6 (DDR2-800), 0x7 (DDR2-1066) - BL4: 0x3 (DDR2-400/533/667), 0x4 (DDR2-800), 0x5 (DDR2-1066) DDR3: - BL8: 0x6 DDR4: - BL8: 5 + WR_PREAMBLE + CRC_MODE WR_PREAMBLE = 1 (1tCK write preamble), 2 (2tCK write preamble) CRC_MODE = 0 (not CRC mode), 1 (CRC mode) LPDDR3: - BL8: 7 + RU(tODTon(max)/tCK) Unit: DFI PHY clock cycles. Programming Mode: Quasi-dynamic Group 1, Group 4
  [20:16] WR_ODT_DELAY — The delay, in DFI PHY clock cycles, from issuing a write command to setting ODT values associated with that command. ODT setting must remain constant for the entire time that DQS is driven by the uMCTL2. Recommended values: DDR2: - CWL + AL - 3 (DDR2-400/533/667), CWL + AL - 4 (DDR2-800), CWL + AL - 5 (DDR2-1066) If (CWL + AL - 3 < 0), uMCTL2 does not support ODT for write operation. DDR3: - 0x0 DDR4: - DFITMG1.dfi_t_cmd_lat (to adjust for CAL mode) LPDDR3: - WL - 1 - RU(tODTon(max)/tCK)) Unit: DFI PHY clock cycles. Programming Mode: Quasi-dynamic Group 1, Group 4
  [11:8] RD_ODT_HOLD — DFI PHY clock cycles to hold ODT for a read command. The minimum supported value is 2. Recommended values: DDR2: - BL8: 0x6 (not DDR2-1066), 0x7 (DDR2-1066) - BL4: 0x4 (not DDR2-1066), 0x5 (DDR2-1066) DDR3: - BL8 - 0x6 DDR4: - BL8: 5 + RD_PREAMBLE RD_PREAMBLE = 1 (1tCK read preamble), 2 (2tCK read preamble) LPDDR3: - BL8: 5 + RU(tDQSCK(max)/tCK) - RD(tDQSCK(min)/tCK) + RU(tODTon(max)/tCK) Unit: DFI PHY clock cycles. Programming Mode: Quasi-dynamic Group 1, Group 4
  [6:2] RD_ODT_DELAY — The delay, in DFI PHY clock cycles, from issuing a read command to setting ODT values associated with that command. ODT setting must remain constant for the entire time that DQS is driven by the uMCTL2. Recommended values: DDR2: - CL + AL - 4 (not DDR2-1066), CL + AL - 5 (DDR2-1066) If (CL + AL - 4 < 0), uMCTL2 does not support ODT for read operation. DDR3: - CL - CWL DDR4: - CL - CWL - RD_PREAMBLE + WR_PREAMBLE + DFITMG1.dfi_t_cmd_lat (to adjust for CAL mode) WR_PREAMBLE = 1 (1tCK write preamble), 2 (2tCK write preamble) RD_PREAMBLE = 1 (1tCK read preamble), 2 (2tCK read preamble) If (CL - CWL - RD_PREAMBLE + WR_PREAMBLE) < 0, uMCTL2 does not support ODT for read operation. LPDDR3: - RL + RD(tDQSCK(min)/tCK) - 1 - RU(tODTon(max)/tCK) Unit: DFI PHY clock cycles. Programming Mode: Quasi-dynamic Group 1, Group 4
